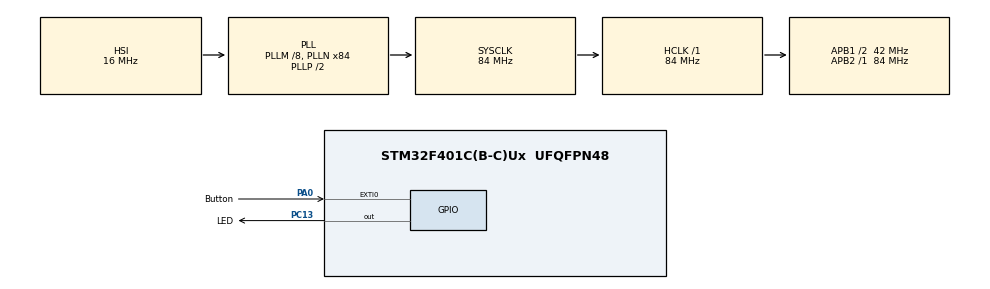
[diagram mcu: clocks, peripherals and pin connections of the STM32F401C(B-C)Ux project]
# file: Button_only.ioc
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FREERTOS.CountingSemaphores01=Task_Sema,2,Dynamic,NULL
FREERTOS.Queues01=funny_queue,16,uint16_t,0,Dynamic,NULL,NULL
FREERTOS.Tasks01=blynky,24,128,blink_handler,Default,NULL,Dynamic,NULL,NULL;interrupt,24,128,Button_IRQ_Handler,Default,NULL,Dynamic,NULL,NULL
FREERTOS.Timers01=SoftTimer1,Timer1_callback,osTimerPeriodic,Default,NULL,Dynamic,NULL
FREERTOS.configENABLE_FPU=1
Mcu.Family=STM32F4
Mcu.Name=STM32F401C(B-C)Ux
Mcu.Package=UFQFPN48
NVIC.PriorityGroup=NVIC_PRIORITYGROUP_4
NVIC.TIM3_IRQn=true\:15\:0\:false\:false\:true\:false\:false\:true\:true
NVIC.TimeBase=TIM3_IRQn
NVIC.TimeBaseIP=TIM3
PA0-WKUP.GPIO_Label=Button
PA0-WKUP.GPIO_PuPd=GPIO_PULLUP
PA0-WKUP.Signal=GPXTI0
PA13.Mode=Serial_Wire
PA13.Signal=SYS_JTMS-SWDIO
PA14.Mode=Serial_Wire
PA14.Signal=SYS_JTCK-SWCLK
PC13-ANTI_TAMP.GPIO_Label=LED
PC13-ANTI_TAMP.GPIO_PuPd=GPIO_PULLUP
PC13-ANTI_TAMP.Signal=GPIO_Output
PH0\ -\ OSC_IN.Mode=HSE-External-Oscillator
PH0\ -\ OSC_IN.Signal=RCC_OSC_IN
PH1\ -\ OSC_OUT.Mode=HSE-External-Oscillator
PH1\ -\ OSC_OUT.Signal=RCC_OSC_OUT
ProjectManager.HeapSize=0x200
ProjectManager.StackSize=0x400
ProjectManager.TargetToolchain=Makefile
RCC.48MHZClocksFreq_Value=42000000
RCC.AHBFreq_Value=84000000
RCC.APB1CLKDivider=RCC_HCLK_DIV2
RCC.APB1Freq_Value=42000000
RCC.APB1TimFreq_Value=84000000
RCC.APB2Freq_Value=84000000
RCC.APB2TimFreq_Value=84000000
RCC.CortexFreq_Value=84000000
RCC.HCLKFreq_Value=84000000
RCC.HSE_VALUE=25000000
RCC.HSI_VALUE=16000000
RCC.LSE_VALUE=32768
RCC.PLLM=8
RCC.PLLN=84
RCC.SYSCLKFreq_VALUE=84000000
RCC.SYSCLKSource=RCC_SYSCLKSOURCE_PLLCLK
RCC.VCOOutputFreq_Value=168000000
VP_FREERTOS_VS_CMSIS_V2.Mode=CMSIS_V2
VP_SYS_VS_tim3.Mode=TIM3
board=custom

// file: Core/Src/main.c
/* USER CODE BEGIN Header */
/**
  ******************************************************************************
  * @file           : main.c
  * @brief          : Main program body
  ******************************************************************************
  * @attention
  *
  * Copyright (c) 2024 STMicroelectronics.
  * All rights reserved.
  *
  * This software is licensed under terms that can be found in the LICENSE file
  * in the root directory of this software component.
  * If no LICENSE file comes with this software, it is provided AS-IS.
  *
  ******************************************************************************
  */
/* USER CODE END Header */
#include "main.h"
#include "cmsis_os.h"

/* Definitions for blynky */
osThreadId_t blynkyHandle;
const osThreadAttr_t blynky_attributes = {
  .name = "blynky",
  .stack_size = 128 * 4,
  .priority = (osPriority_t) osPriorityNormal,
};
/* Definitions for interrupt */
osThreadId_t interruptHandle;
const osThreadAttr_t interrupt_attributes = {
  .name = "interrupt",
  .stack_size = 128 * 4,
  .priority = (osPriority_t) osPriorityNormal,
};
/* Definitions for funny_queue */
osMessageQueueId_t funny_queueHandle;
const osMessageQueueAttr_t funny_queue_attributes = {
  .name = "funny_queue"
};
/* Definitions for SoftTimer1 */
osTimerId_t SoftTimer1Handle;
const osTimerAttr_t SoftTimer1_attributes = {
  .name = "SoftTimer1"
};
/* Definitions for Task_Sema */
osSemaphoreId_t Task_SemaHandle;
const osSemaphoreAttr_t Task_Sema_attributes = {
  .name = "Task_Sema"
};

void SystemClock_Config(void);
static void MX_GPIO_Init(void);
void blink_handler(void *argument);
void Button_IRQ_Handler(void *argument);
void Timer1_callback(void *argument);

int main(void)
{

  /* MCU Configuration--------------------------------------------------------*/

  /* Reset of all peripherals, Initializes the Flash interface and the Systick. */
  HAL_Init();

  /* Configure the system clock */
  SystemClock_Config();

  /* Initialize all configured peripherals */
  MX_GPIO_Init();

  /* Init scheduler */
  osKernelInitialize();

  /* Create the semaphores(s) */
  /* creation of Task_Sema */
  Task_SemaHandle = osSemaphoreNew(2, 2, &Task_Sema_attributes);

  /* Create the timer(s) */
  /* creation of SoftTimer1 */
  SoftTimer1Handle = osTimerNew(Timer1_callback, osTimerPeriodic, NULL, &SoftTimer1_attributes);

  /* Create the queue(s) */
  /* creation of funny_queue */
  funny_queueHandle = osMessageQueueNew (16, sizeof(uint16_t), &funny_queue_attributes);

  /* Create the thread(s) */
  /* creation of blynky */
  blynkyHandle = osThreadNew(blink_handler, NULL, &blynky_attributes);

  /* creation of interrupt */
  interruptHandle = osThreadNew(Button_IRQ_Handler, NULL, &interrupt_attributes);

  /* Start scheduler */
  osKernelStart();

  /* We should never get here as control is now taken by the scheduler */
  /* Infinite loop */
  while (1)
  {

  }
}

void SystemClock_Config(void)
{
  RCC_OscInitTypeDef RCC_OscInitStruct = {0};
  RCC_ClkInitTypeDef RCC_ClkInitStruct = {0};

  /** Configure the main internal regulator output voltage
  */
  __HAL_RCC_PWR_CLK_ENABLE();
  __HAL_PWR_VOLTAGESCALING_CONFIG(PWR_REGULATOR_VOLTAGE_SCALE2);

  /** Initializes the RCC Oscillators according to the specified parameters
  * in the RCC_OscInitTypeDef structure.
  */
  RCC_OscInitStruct.OscillatorType = RCC_OSCILLATORTYPE_HSI;
  RCC_OscInitStruct.HSIState = RCC_HSI_ON;
  RCC_OscInitStruct.HSICalibrationValue = RCC_HSICALIBRATION_DEFAULT;
  RCC_OscInitStruct.PLL.PLLState = RCC_PLL_ON;
  RCC_OscInitStruct.PLL.PLLSource = RCC_PLLSOURCE_HSI;
  RCC_OscInitStruct.PLL.PLLM = 8;
  RCC_OscInitStruct.PLL.PLLN = 84;
  RCC_OscInitStruct.PLL.PLLP = RCC_PLLP_DIV2;
  RCC_OscInitStruct.PLL.PLLQ = 4;
  if (HAL_RCC_OscConfig(&RCC_OscInitStruct) != HAL_OK)
  {
    Error_Handler();
  }

  /** Initializes the CPU, AHB and APB buses clocks
  */
  RCC_ClkInitStruct.ClockType = RCC_CLOCKTYPE_HCLK|RCC_CLOCKTYPE_SYSCLK
                              |RCC_CLOCKTYPE_PCLK1|RCC_CLOCKTYPE_PCLK2;
  RCC_ClkInitStruct.SYSCLKSource = RCC_SYSCLKSOURCE_PLLCLK;
  RCC_ClkInitStruct.AHBCLKDivider = RCC_SYSCLK_DIV1;
  RCC_ClkInitStruct.APB1CLKDivider = RCC_HCLK_DIV2;
  RCC_ClkInitStruct.APB2CLKDivider = RCC_HCLK_DIV1;

  if (HAL_RCC_ClockConfig(&RCC_ClkInitStruct, FLASH_LATENCY_2) != HAL_OK)
  {
    Error_Handler();
  }
}

static void MX_GPIO_Init(void)
{
  GPIO_InitTypeDef GPIO_InitStruct = {0};

  /* GPIO Ports Clock Enable */
  __HAL_RCC_GPIOC_CLK_ENABLE();
  __HAL_RCC_GPIOH_CLK_ENABLE();
  __HAL_RCC_GPIOA_CLK_ENABLE();

  /*Configure GPIO pin Output Level */
  HAL_GPIO_WritePin(LED_GPIO_Port, LED_Pin, GPIO_PIN_RESET);

  /*Configure GPIO pin : LED_Pin */
  GPIO_InitStruct.Pin = LED_Pin;
  GPIO_InitStruct.Mode = GPIO_MODE_OUTPUT_PP;
  GPIO_InitStruct.Pull = GPIO_PULLUP;
  GPIO_InitStruct.Speed = GPIO_SPEED_FREQ_LOW;
  HAL_GPIO_Init(LED_GPIO_Port, &GPIO_InitStruct);

  /*Configure GPIO pin : Button_Pin */
  GPIO_InitStruct.Pin = Button_Pin;
  GPIO_InitStruct.Mode = GPIO_MODE_IT_RISING;
  GPIO_InitStruct.Pull = GPIO_PULLUP;
  HAL_GPIO_Init(Button_GPIO_Port, &GPIO_InitStruct);

}

/* USER CODE BEGIN 4 */
HAL_GPIO_EXTI_Callback(uint16_t GPIO_Pin)
{
  if(GPIO_Pin == Button_Pin)
  {
    HAL_GPIO_TogglePin(LED_GPIO_Port, LED_Pin);

    osThreadSuspend(blynkyHandle);
    //osSemaphoreWait(Task_SemaHandle, osWaitForever);
  }
}
/* USER CODE END 4 */

void blink_handler(void *argument)
{
  /* USER CODE BEGIN 5 */
  /* Infinite loop */
  for(;;)
  {
    osThreadSuspend(interruptHandle);
    //HAL_GPIO_TogglePin(LED_GPIO_Port, LED_Pin);
    HAL_GPIO_WritePin(LED_GPIO_Port, LED_Pin, GPIO_PIN_RESET);
    osDelay(500);
  }
  /* USER CODE END 5 */
}

void Button_IRQ_Handler(void *argument)
{
  for(;;)
  {
  }
}

/* Timer1_callback function */
void Timer1_callback(void *argument)
{
}

void HAL_TIM_PeriodElapsedCallback(TIM_HandleTypeDef *htim)
{
  if (htim->Instance == TIM3) {
    HAL_IncTick();
  }
}

void Error_Handler(void)
{
  __disable_irq();
  while (1)
  {
  }
}
